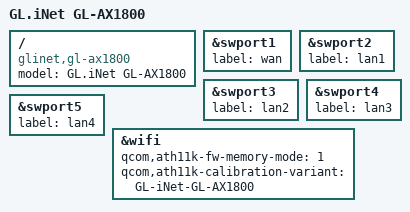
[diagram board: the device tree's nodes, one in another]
// SPDX-License-Identifier: GPL-2.0-or-later OR MIT

/dts-v1/;

#include "ipq6000-glinet.dtsi"

/ {
	model = "GL.iNet GL-AX1800";
	compatible = "glinet,gl-ax1800", "qcom,ipq6018";
};

&swport1 {
	status = "okay";
	label = "wan";
};

&swport2 {
	status = "okay";
	label = "lan1";
};

&swport3 {
	status = "okay";
	label = "lan2";
};

&swport4 {
	status = "okay";
	label = "lan3";
};

&swport5 {
	status = "okay";
	label = "lan4";
};

&wifi {
	status = "okay";
	qcom,ath11k-fw-memory-mode = <1>;
	qcom,ath11k-calibration-variant = "GL-iNet-GL-AX1800";
};
